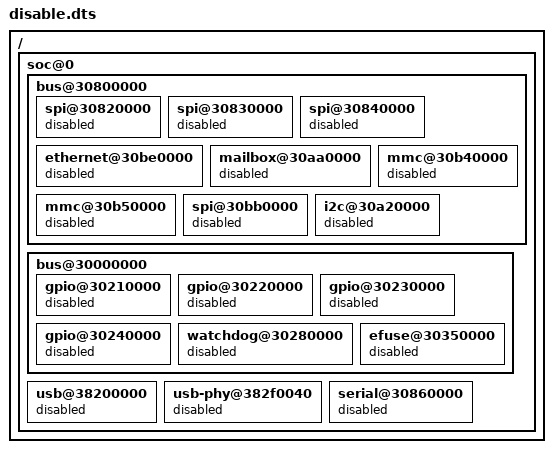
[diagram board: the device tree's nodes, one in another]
/ {

    soc@0 {
        bus@30800000 {
            spi@30820000 {
                status = "disabled";
            };

            spi@30830000 {
                status = "disabled";
            };

            spi@30840000 {
                status = "disabled";
            };

            ethernet@30be0000 {
                status = "disabled";
            };

            mailbox@30aa0000 {
                status = "disabled";
            };

            mmc@30b40000 {
                status = "disabled";
            };

            mmc@30b50000 {
                status = "disabled";
            };

            spi@30bb0000 {
                status = "disabled";
            };

            i2c@30a20000 {
                status = "disabled";
            };
        };

        bus@30000000 {
            gpio@30210000 {
                status = "disabled";
            };

            gpio@30220000 {
                status = "disabled";
            };

            gpio@30230000 {
                status = "disabled";
            };

            gpio@30240000 {
                status = "disabled";
            };

            watchdog@30280000 {
                status = "disabled";
            };

            efuse@30350000 {
                status = "disabled";
            };
        };

        usb@38200000 {
            status = "disabled";
        };

        usb-phy@382f0040 {
            status = "disabled";
        };

        serial@30860000 {
            status = "disabled";
        };
    };
};
